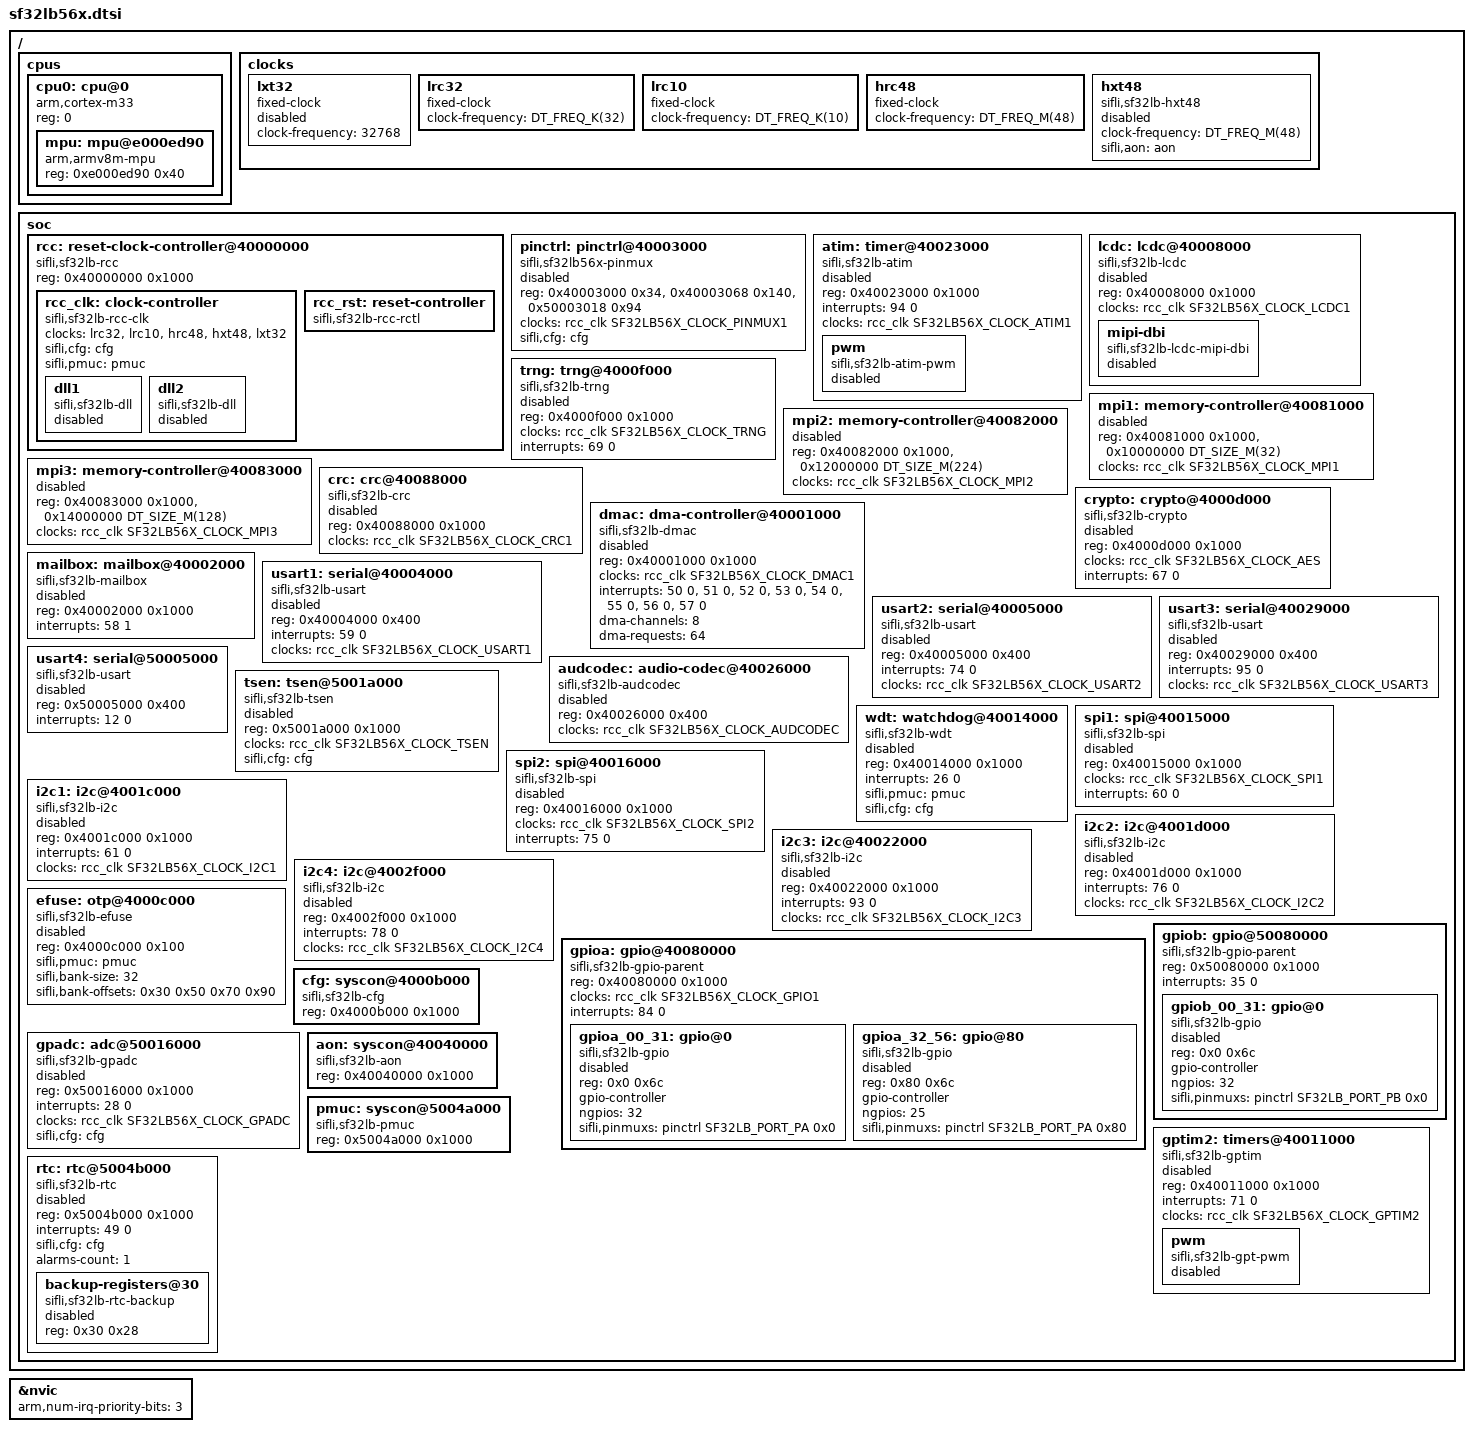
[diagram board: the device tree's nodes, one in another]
/*
 * Copyright (c) 2025 Core Devices LLC
 * Copyright (c) 2025 SiFli Technologies(Nanjing) Co., Ltd
 * SPDX-License-Identifier: Apache-2.0
 */

#include <arm/armv8-m.dtsi>
#include <freq.h>
#include <mem.h>

#include <zephyr/dt-bindings/clock/sf32lb56x-clocks.h>
#include <zephyr/dt-bindings/pinctrl/sf32lb56x-pinctrl.h>

/ {
	cpus {
		#address-cells = <1>;
		#size-cells = <0>;

		cpu0: cpu@0 {
			compatible = "arm,cortex-m33";
			reg = <0>;
			#address-cells = <1>;
			#size-cells = <1>;

			mpu: mpu@e000ed90 {
				compatible = "arm,armv8m-mpu";
				reg = <0xe000ed90 0x40>;
			};
		};
	};

	clocks {
		lxt32: lxt32 {
			compatible = "fixed-clock";
			clock-frequency = <32768>;
			#clock-cells = <0>;
			status = "disabled";
		};

		lrc32: lrc32 {
			compatible = "fixed-clock";
			clock-frequency = <DT_FREQ_K(32)>;
			#clock-cells = <0>;
		};

		lrc10: lrc10 {
			compatible = "fixed-clock";
			clock-frequency = <DT_FREQ_K(10)>;
			#clock-cells = <0>;
		};

		hrc48: hrc48 {
			compatible = "fixed-clock";
			clock-frequency = <DT_FREQ_M(48)>;
			#clock-cells = <0>;
		};

		hxt48: hxt48 {
			compatible = "sifli,sf32lb-hxt48";
			clock-frequency = <DT_FREQ_M(48)>;
			#clock-cells = <0>;
			sifli,aon = <&aon>;
			status = "disabled";
		};
	};

	soc {
		rcc: reset-clock-controller@40000000 {
			compatible = "sifli,sf32lb-rcc";
			reg = <0x40000000 0x1000>;

			rcc_clk: clock-controller {
				compatible = "sifli,sf32lb-rcc-clk";
				clocks = <&lrc32>, <&lrc10>, <&hrc48>, <&hxt48>,
					 <&lxt32>;
				clock-names = "lrc32", "lrc10", "hrc48",
					      "hxt48", "lxt32";
				#clock-cells = <1>;
				sifli,cfg = <&cfg>;
				sifli,pmuc = <&pmuc>;

				dll1: dll1 {
					compatible = "sifli,sf32lb-dll";
					status = "disabled";
				};

				dll2: dll2 {
					compatible = "sifli,sf32lb-dll";
					status = "disabled";
				};
			};

			rcc_rst: reset-controller {
				compatible = "sifli,sf32lb-rcc-rctl";
				#reset-cells = <1>;
			};
		};

		pinctrl: pinctrl@40003000 {
			compatible = "sifli,sf32lb56x-pinmux";
			/*
			 * SF32LB56 has 13 SB pad registers (SB00-SB12) between SA and PA,
			 * unlike SF32LB52 where PA follows SA directly.
			 * HPSYS Layout: SA00-SA12 (0x00-0x30), SB00-SB12 (0x34-0x64), PA00-PA78 (0x68+).
			 * pad_pa base = 0x40003000 + 26*4 = 0x40003068, size = 79*4 + 4(CR) = 0x140.
			 * LPSYS PINMUX2 @ 0x50003000: PAD_SC00-SC05 (0x00-0x14), PAD_PB00 starts at 0x18.
			 * pad_pb base = 0x50003018, size = 37*4 = 0x94 (PB00-PB36).
			 */
			reg = <0x40003000 0x34>, <0x40003068 0x140>, <0x50003018 0x94>;
			reg-names = "pad_sa", "pad_pa", "pad_pb";
			clocks = <&rcc_clk SF32LB56X_CLOCK_PINMUX1>;
			#sifli,pinmux-cells = <2>;
			sifli,cfg = <&cfg>;
			status = "disabled";
		};

		atim: timer@40023000 {
			compatible = "sifli,sf32lb-atim";
			reg = <0x40023000 0x1000>;
			interrupts = <94 0>;
			clocks = <&rcc_clk SF32LB56X_CLOCK_ATIM1>;
			status = "disabled";

			pwm {
				compatible = "sifli,sf32lb-atim-pwm";
				#pwm-cells = <3>;
				status = "disabled";
			};
		};

		lcdc: lcdc@40008000 {
			compatible = "sifli,sf32lb-lcdc";
			reg = <0x40008000 0x1000>;
			clocks = <&rcc_clk SF32LB56X_CLOCK_LCDC1>;
			status = "disabled";

			mipi-dbi {
				compatible = "sifli,sf32lb-lcdc-mipi-dbi";
				#address-cells = <1>;
				#size-cells = <0>;
				status = "disabled";
			};
		};

		trng: trng@4000f000 {
			compatible = "sifli,sf32lb-trng";
			reg = <0x4000f000 0x1000>;
			clocks = <&rcc_clk SF32LB56X_CLOCK_TRNG>;
			interrupts = <69 0>;
			status = "disabled";
		};

		mpi1: memory-controller@40081000 {
			/*
			 * configure compatible depending on memory type, choices:
			 * - sifli,sf32lb-mpi-qspi-nor
			 */
			reg = <0x40081000 0x1000>, <0x10000000 DT_SIZE_M(32)>;
			reg-names = "ctrl", "nor";
			clocks = <&rcc_clk SF32LB56X_CLOCK_MPI1>;
			#address-cells = <1>;
			#size-cells = <0>;
			status = "disabled";
		};

		mpi2: memory-controller@40082000 {
			/*
			 * configure compatible depending on memory type, choices:
			 * - sifli,sf32lb-mpi-qspi-nor
			 */
			reg = <0x40082000 0x1000>, <0x12000000 DT_SIZE_M(224)>;
			reg-names = "ctrl", "nor";
			#address-cells = <1>;
			#size-cells = <0>;
			clocks = <&rcc_clk SF32LB56X_CLOCK_MPI2>;
			status = "disabled";
		};

		mpi3: memory-controller@40083000 {
			/*
			 * configure compatible depending on memory type, choices:
			 * - sifli,sf32lb-mpi-qspi-nor
			 */
			reg = <0x40083000 0x1000>, <0x14000000 DT_SIZE_M(128)>;
			reg-names = "ctrl", "nor";
			clocks = <&rcc_clk SF32LB56X_CLOCK_MPI3>;
			#address-cells = <1>;
			#size-cells = <0>;
			status = "disabled";
		};

		crc: crc@40088000 {
			compatible = "sifli,sf32lb-crc";
			reg = <0x40088000 0x1000>;
			clocks = <&rcc_clk SF32LB56X_CLOCK_CRC1>;
			status = "disabled";
		};

		crypto: crypto@4000d000 {
			compatible = "sifli,sf32lb-crypto";
			reg = <0x4000d000 0x1000>;
			clocks = <&rcc_clk SF32LB56X_CLOCK_AES>;
			interrupts = <67 0>;
			status = "disabled";
		};

		dmac: dma-controller@40001000 {
			compatible = "sifli,sf32lb-dmac";
			reg = <0x40001000 0x1000>;
			clocks = <&rcc_clk SF32LB56X_CLOCK_DMAC1>;
			interrupts = <50 0>, <51 0>, <52 0>, <53 0>,
				     <54 0>, <55 0>, <56 0>, <57 0>;
			dma-channels = <8>;
			dma-requests = <64>;
			#dma-cells = <3>;
			status = "disabled";
		};

		mailbox: mailbox@40002000 {
			compatible = "sifli,sf32lb-mailbox";
			reg = <0x40002000 0x1000>;
			interrupts = <58 1>;
			status = "disabled";
		};

		usart1: serial@40004000 {
			compatible = "sifli,sf32lb-usart";
			reg = <0x40004000 0x400>;
			interrupts = <59 0>;
			clocks = <&rcc_clk SF32LB56X_CLOCK_USART1>;
			status = "disabled";
		};

		usart2: serial@40005000 {
			compatible = "sifli,sf32lb-usart";
			reg = <0x40005000 0x400>;
			interrupts = <74 0>;
			clocks = <&rcc_clk SF32LB56X_CLOCK_USART2>;
			status = "disabled";
		};

		usart3: serial@40029000 {
			compatible = "sifli,sf32lb-usart";
			reg = <0x40029000 0x400>;
			interrupts = <95 0>;
			clocks = <&rcc_clk SF32LB56X_CLOCK_USART3>;
			status = "disabled";
		};

		/* USART4-6 are LPSYS peripherals (0x5000xxxx) */
		usart4: serial@50005000 {
			compatible = "sifli,sf32lb-usart";
			reg = <0x50005000 0x400>;
			interrupts = <12 0>;  /* USART4_IRQn = 12 */
			status = "disabled";
		};

		audcodec: audio-codec@40026000 {
			compatible = "sifli,sf32lb-audcodec";
			reg = <0x40026000 0x400>;
			clocks = <&rcc_clk SF32LB56X_CLOCK_AUDCODEC>;
			status = "disabled";
		};

		tsen: tsen@5001a000 {
			compatible = "sifli,sf32lb-tsen";
			reg = <0x5001a000 0x1000>;
			clocks = <&rcc_clk SF32LB56X_CLOCK_TSEN>;
			sifli,cfg = <&cfg>;
			status = "disabled";
		};

		wdt: watchdog@40014000 {
			compatible = "sifli,sf32lb-wdt";
			reg = <0x40014000 0x1000>;
			interrupts = <26 0>; /* shared with BTIM4 — same as LB52 upstream */
			sifli,pmuc = <&pmuc>;
			sifli,cfg = <&cfg>;
			status = "disabled";
		};

		spi1: spi@40015000 {
			compatible = "sifli,sf32lb-spi";
			#address-cells = <1>;
			#size-cells = <0>;
			reg = <0x40015000 0x1000>;
			clocks = <&rcc_clk SF32LB56X_CLOCK_SPI1>;
			interrupts = <60 0>;
			status = "disabled";
		};

		spi2: spi@40016000 {
			compatible = "sifli,sf32lb-spi";
			#address-cells = <1>;
			#size-cells = <0>;
			reg = <0x40016000 0x1000>;
			clocks = <&rcc_clk SF32LB56X_CLOCK_SPI2>;
			interrupts = <75 0>;
			status = "disabled";
		};

		i2c1: i2c@4001c000 {
			compatible = "sifli,sf32lb-i2c";
			reg = <0x4001c000 0x1000>;
			interrupts = <61 0>;
			#address-cells = <1>;
			#size-cells = <0>;
			clocks = <&rcc_clk SF32LB56X_CLOCK_I2C1>;
			status = "disabled";
		};

		i2c2: i2c@4001d000 {
			compatible = "sifli,sf32lb-i2c";
			reg = <0x4001d000 0x1000>;
			interrupts = <76 0>;
			#address-cells = <1>;
			#size-cells = <0>;
			clocks = <&rcc_clk SF32LB56X_CLOCK_I2C2>;
			status = "disabled";
		};

		i2c3: i2c@40022000 {
			compatible = "sifli,sf32lb-i2c";
			reg = <0x40022000 0x1000>;
			interrupts = <93 0>;
			#address-cells = <1>;
			#size-cells = <0>;
			clocks = <&rcc_clk SF32LB56X_CLOCK_I2C3>;
			status = "disabled";
		};

		i2c4: i2c@4002f000 {
			compatible = "sifli,sf32lb-i2c";
			reg = <0x4002f000 0x1000>;
			interrupts = <78 0>;
			#address-cells = <1>;
			#size-cells = <0>;
			clocks = <&rcc_clk SF32LB56X_CLOCK_I2C4>;
			status = "disabled";
		};

		gpioa: gpio@40080000 {
			compatible = "sifli,sf32lb-gpio-parent";
			reg = <0x40080000 0x1000>;
			ranges = <0x0 0x40080000 0x1000>;
			#address-cells = <1>;
			#size-cells = <1>;
			clocks = <&rcc_clk SF32LB56X_CLOCK_GPIO1>;
			interrupts = <84 0>;

			/*
			 * Split into 32 pin blocks due to Zephyr requiring GPIO
			 * ports to have a maximum of 32 pins. This is a
			 * Zephyrism, but it is what it is!
			 */
			gpioa_00_31: gpio@0 {
				compatible = "sifli,sf32lb-gpio";
				reg = <0x0 0x6c>;
				#gpio-cells = <2>;
				gpio-controller;
				ngpios = <32>;
				sifli,pinmuxs = <&pinctrl SF32LB_PORT_PA 0x0>;
				status = "disabled";
			};

			gpioa_32_56: gpio@80 {
				compatible = "sifli,sf32lb-gpio";
				reg = <0x80 0x6c>;
				#gpio-cells = <2>;
				gpio-controller;
				ngpios = <25>;  /* PA32-PA56 (25 pins) */
				sifli,pinmuxs = <&pinctrl SF32LB_PORT_PA 0x80>;
				status = "disabled";
			};
		};

		/*
		 * LPSYS GPIO2 (PB pins). Clock is enabled early in soc_early_init_hook
		 * via LPSYS_RCC_ENR2 bit 0 — LPSYS RCC is not yet managed by Zephyr
		 * clock control, so no clocks property here.
		 * Pinmux: PINMUX2 @ 0x50003000; pad_pb base = 0x50003018 (PAD_PB00, after 6 SC regs).
		 */
		gpiob: gpio@50080000 {
			compatible = "sifli,sf32lb-gpio-parent";
			reg = <0x50080000 0x1000>;
			ranges = <0x0 0x50080000 0x1000>;
			#address-cells = <1>;
			#size-cells = <1>;
			interrupts = <35 0>;

			gpiob_00_31: gpio@0 {
				compatible = "sifli,sf32lb-gpio";
				reg = <0x0 0x6c>;
				#gpio-cells = <2>;
				gpio-controller;
				ngpios = <32>;
				sifli,pinmuxs = <&pinctrl SF32LB_PORT_PB 0x0>;
				status = "disabled";
			};
		};

		efuse: otp@4000c000 {
			compatible = "sifli,sf32lb-efuse";
			reg = <0x4000c000 0x100>;
			sifli,pmuc = <&pmuc>;
			sifli,bank-size = <32>;
			sifli,bank-offsets = <0x30 0x50 0x70 0x90>;
			status = "disabled";
		};

		cfg: syscon@4000b000 {
			compatible = "sifli,sf32lb-cfg", "syscon";
			reg = <0x4000b000 0x1000>;
		};

		gpadc: adc@50016000 {
			compatible = "sifli,sf32lb-gpadc";
			reg = <0x50016000 0x1000>;
			interrupts = <28 0>; /* LPSYS IRQ — needs cross-core routing */
			clocks = <&rcc_clk SF32LB56X_CLOCK_GPADC>;
			sifli,cfg = <&cfg>;
			#io-channel-cells = <1>;
			status = "disabled";
		};

		gptim2: timers@40011000 {
			compatible = "sifli,sf32lb-gptim";
			reg = <0x40011000 0x1000>;
			interrupts = <71 0>;
			clocks = <&rcc_clk SF32LB56X_CLOCK_GPTIM2>;
			status = "disabled";

			pwm {
				compatible = "sifli,sf32lb-gpt-pwm";
				#pwm-cells = <3>;
				status = "disabled";
			};
		};

		aon: syscon@40040000 {
			compatible = "sifli,sf32lb-aon", "syscon";
			reg = <0x40040000 0x1000>;
		};

		pmuc: syscon@5004a000 {
			compatible = "sifli,sf32lb-pmuc", "syscon";
			reg = <0x5004a000 0x1000>;
		};

		rtc: rtc@5004b000 {
			compatible = "sifli,sf32lb-rtc";
			reg = <0x5004b000 0x1000>;
			ranges = <0x0 0x5004b000 0x1000>;
			#address-cells = <1>;
			#size-cells = <1>;
			interrupts = <49 0>;
			sifli,cfg = <&cfg>;
			alarms-count = <1>;
			status = "disabled";

			backup-registers@30 {
				compatible = "sifli,sf32lb-rtc-backup";
				reg = <0x30 0x28>;
				status = "disabled";
			};
		};
	};
};

&nvic {
	arm,num-irq-priority-bits = <3>;
};
